# RT58X register map
Series: ARMv8-M Mainline; File version: 1.0
CPU: CM3 r0p0, little endian, MPU, no FPU, VTOR, 3 interrupt priority bits
Registers are 32-bit, read-write, reset 0x0 unless marked. A register's access mark holds for its fields unless they carry their own. Offsets are from the block's base; [hi:lo] are bit positions.

## RTC — RTC Register block
Base 0x40600000
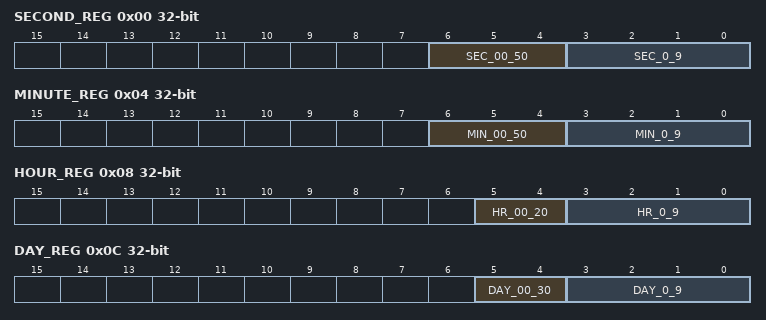
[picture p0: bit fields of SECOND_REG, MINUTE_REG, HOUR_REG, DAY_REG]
0x00 SECOND_REG — second
  [6:4] SEC_00_50 — Tens place of seconds (BCD)
    0=B_4_to_6 (Tens place of seconds (BCD))
  [3:0] SEC_0_9 — Units place of seconds (BCD)
    0=B_0_to_3 (Units place of seconds (BCD))
0x04 MINUTE_REG — minute
  [6:4] MIN_00_50 — Tens place of minutes (BCD)
    0=B_4_to_6 (Tens place of minutes (BCD))
  [3:0] MIN_0_9 — Units place of minutes (BCD)
    0=B_0_to_3 (Units place of minutes (BCD))
0x08 HOUR_REG — hour
  [5:4] HR_00_20 — Tens place of hours (BCD)
    0=B_4_to_5 (Tens place of hours (BCD))
  [3:0] HR_0_9 — Units place of hours (BCD)
    0=B_0_to_3 (Units place of hours (BCD))
0x0C DAY_REG — day
  [5:4] DAY_00_30 — Tens place of days (BCD)
    0=B_4_to_5 (Tens place of days (BCD))
  [3:0] DAY_0_9 — Units place of days (BCD)
    0=B_0_to_3 (Units place of days (BCD))
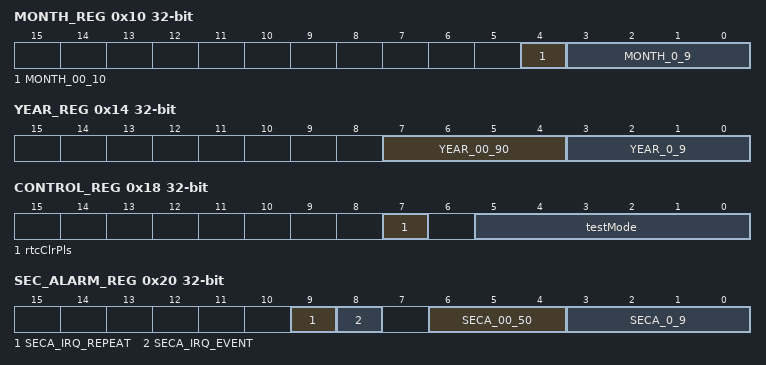
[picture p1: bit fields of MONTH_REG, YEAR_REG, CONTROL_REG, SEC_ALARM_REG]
0x10 MONTH_REG — month
  [4] MONTH_00_10 — Tens place of months (BCD)
    0=B_4 (Tens place of months (BCD))
  [3:0] MONTH_0_9 — Units place of months (BCD)
    0=B_0_to_3 (Units place of months (BCD))
0x14 YEAR_REG — year
  [7:4] YEAR_00_90 — Tens place of years (BCD)
    0=B_4_to_7 (Tens place of years (BCD))
  [3:0] YEAR_0_9 — Units place of years (BCD)
    0=B_0_to_3 (Units place of years (BCD))
0x18 CONTROL_REG — control
  [7] rtcClrPls — When 1 is written, creates a pulse on the clk32k domain to clear all counters and values there to their initial state. A write of 0 to this bit has no effect. Read: 1=Clear in progress, 0=Clear done.
    0=B_7 (When 1 is written, creates a pulse on the clk32k domain to clear all counters and values there to their initial state. A write of 0 to this bit has no effect. Read: 1=Clear in progress, 0=Clear done.)
  [5:0] testMode — Used to speed up Time Unit counters for test. If a bit is set to 1, then the corresponding time unit counter will change on the same timing as Seconds. [0]=Unused, [1]=Minutes, [2]=Hours, [3]=Days, [4]=Months, [5]=Years.
    0=B_0_to_5 (Used to speed up Time Unit counters for test. If a bit is set to 1, then the corresponding time unit counter will change on the same timing as Seconds. [0]=Unused, [1]=Minutes, [2]=Hours, [3]=Days, [4]=Months, [5]=Years.)
0x1C CLK_DIV_REG reset 0x7CFF — clk div
  [15:0] clkDiv — Clock Divisor for generating a 1Hz enable to the Seconds Counter. The Clock Divisor value (D) and the input clock frequency (F) are related by the following equation: D = F - 1
0x20 SEC_ALARM_REG — sec alarm
  [9] SECA_IRQ_REPEAT — When set, configures the event interrupt to trigger every second. When clear, seconds = seconds alarm for the event interrupt to be triggered.
    0=B_9 (When set, configures the event interrupt to trigger every second. When clear, seconds = seconds alarm for the event interrupt to be triggered.)
  [8] SECA_IRQ_EVENT — When set, configures the seconds interrupt to trigger every second. When clear, the seconds interrupt will be triggered once per minute, when seconds = seconds alarm.
    0=B_8 (When set, configures the seconds interrupt to trigger every second. When clear, the seconds interrupt will be triggered once per minute, when seconds = seconds alarm.)
  [6:4] SECA_00_50 — Tens place of seconds alarm (BCD)
    0=B_4_to_6 (Tens place of seconds alarm (BCD))
  [3:0] SECA_0_9 — Units place of seconds alarm (BCD)
    0=B_0_to_3 (Units place of seconds alarm (BCD))
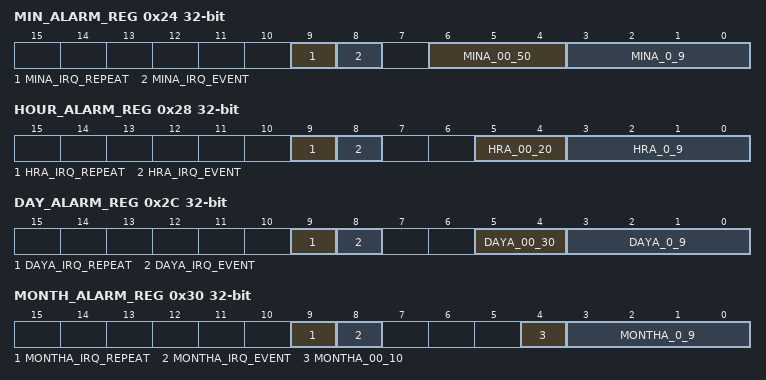
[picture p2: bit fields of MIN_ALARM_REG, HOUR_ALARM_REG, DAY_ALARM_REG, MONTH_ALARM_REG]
0x24 MIN_ALARM_REG — min alarm
  [9] MINA_IRQ_REPEAT — Note: This field is relevant only when SECA_IRQ_REPEAT is NOT set. When set, configures the event interrupt to trigger every minute when seconds = seconds alarm. When clear, seconds = seconds alarm AND minutes = minutes alarm for the event interrupt to be triggered.
    0=B_9 (Note: This field is relevant only when SECA_IRQ_REPEAT is NOT set. When set, configures the event interrupt to trigger every minute when seconds = seconds alarm. When clear, seconds = seconds alarm AND minutes = minutes alarm for the event interrupt to be triggered.)
  [8] MINA_IRQ_EVENT — When set, configures the minutes interrupt to trigger on the first second in each new minute. When clear, the minutes interrupt will be triggered once per hour, on the first second of the minute in which minutes = minutes alarm.
    0=B_8 (When set, configures the minutes interrupt to trigger on the first second in each new minute. When clear, the minutes interrupt will be triggered once per hour, on the first second of the minute in which minutes = minutes alarm.)
  [6:4] MINA_00_50 — Tens place of minutes alarm (BCD)
    0=B_4_to_6 (Tens place of minutes alarm (BCD))
  [3:0] MINA_0_9 — Units place of minutes alarm (BCD)
    0=B_0_to_3 (Units place of minutes alarm (BCD))
0x28 HOUR_ALARM_REG — hour alarm
  [9] HRA_IRQ_REPEAT — Note: This field is relevant only when MINA_IRQ_REPEAT and SECA_IRQ_PEPEAT are NOT set. When set, configures the event interrupt to trigger every hour when seconds = seconds alarm AND minutes = minutes alarm. When clear, seconds = seconds alarm AND minutes = minutes alarm AND hours = hours alarm for the event interrupt to be triggered.
    0=B_9 (Note: This field is relevant only when MINA_IRQ_REPEAT and SECA_IRQ_PEPEAT are NOT set. When set, configures the event interrupt to trigger every hour when seconds = seconds alarm AND minutes = minutes alarm. When clear, seconds = seconds alarm AND minutes = minutes alarm AND hours = hours alarm for the event interrupt to be triggered.)
  [8] HRA_IRQ_EVENT — When set, configures the hours interrupt to trigger on the first second in each new hour. When clear, the hours interrupt will be triggered once per day, on the first second of the hour in which hours = hours alarm.
    0=B_8 (When set, configures the hours interrupt to trigger on the first second in each new hour. When clear, the hours interrupt will be triggered once per day, on the first second of the hour in which hours = hours alarm.)
  [5:4] HRA_00_20 — Tens place of hours alarm (BCD)
    0=B_4_to_5 (Tens place of hours alarm (BCD))
  [3:0] HRA_0_9 — Units place of hours alarm (BCD)
    0=B_0_to_3 (Units place of hours alarm (BCD))
0x2C DAY_ALARM_REG — day alarm
  [9] DAYA_IRQ_REPEAT — Note: This field is relevant only when HRA_IRQ_REPEAT, MINA_IRQ_REPEAT and SECA_IRQ_REPEAT are NOT set. When set, configures the event interrupt to trigger every day when seconds = seconds alarm AND minutes = minutes alarm AND hours = hours alarm. When clear, seconds = seconds alarm AND minutes = minutes alarm AND hours = hours alarm AND days = days alarm for the event interrupt to be triggered.
    0=B_9 (Note: This field is relevant only when HRA_IRQ_REPEAT, MINA_IRQ_REPEAT and SECA_IRQ_REPEAT are NOT set. When set, configures the event interrupt to trigger every day when seconds = seconds alarm AND minutes = minutes alarm AND hours = hours alarm. When clear, seconds = seconds alarm AND minutes = minutes alarm AND hours = hours alarm AND days = days alarm for the event interrupt to be triggered.)
  [8] DAYA_IRQ_EVENT — When set, configures the days interrupt to trigger on the first second in each new day. When clear, the days interrupt will be triggered once per month, on the first second of the day in which days = days alarm.
    0=B_8 (When set, configures the days interrupt to trigger on the first second in each new day. When clear, the days interrupt will be triggered once per month, on the first second of the day in which days = days alarm.)
  [5:4] DAYA_00_30 — Tens place of days alarm (BCD)
    0=B_4_to_5 (Tens place of days alarm (BCD))
  [3:0] DAYA_0_9 — Units place of days alarm (BCD)
    0=B_0_to_3 (Units place of days alarm (BCD))
0x30 MONTH_ALARM_REG — month alarm
  [9] MONTHA_IRQ_REPEAT — Note: This field is relevant only when DAYA_IRQ_REPEAT, HRA_IRQ_REPEAT, MINA_IRQ_REPEAT and SECA_IRQ_REPEAT are NOT set. When set configures the event interrupt to trigger every month when seconds = seconds alarm AND minutes = minutes alarm AND hours = hours alarm AND days = days alarm. When clear, seconds = seconds alarm AND minutes = minutes alarm AND hours = hours alarm AND days = days alarm AND months = months alarm for the event interrupt to be triggered.
    0=B_9 (Note: This field is relevant only when DAYA_IRQ_REPEAT, HRA_IRQ_REPEAT, MINA_IRQ_REPEAT and SECA_IRQ_REPEAT are NOT set. When set configures the event interrupt to trigger every month when seconds = seconds alarm AND minutes = minutes alarm AND hours = hours alarm AND days = days alarm. When clear, seconds = seconds alarm AND minutes = minutes alarm AND hours = hours alarm AND days = days alarm AND months = months alarm for the event interrupt to be triggered.)
  [8] MONTHA_IRQ_EVENT — When set, configures the months interrupt to trigger on the first second in each new month. When clear, the months interrupt will be triggered once per year, on the first second of the month in which months = months alarm.
    0=B_8 (When set, configures the months interrupt to trigger on the first second in each new month. When clear, the months interrupt will be triggered once per year, on the first second of the month in which months = months alarm.)
  [4] MONTHA_00_10 — Tens place of months alarm (BCD)
    0=B_4 (Tens place of months alarm (BCD))
  [3:0] MONTHA_0_9 — Units place of months alarm (BCD)
    0=B_0_to_3 (Units place of months alarm (BCD))
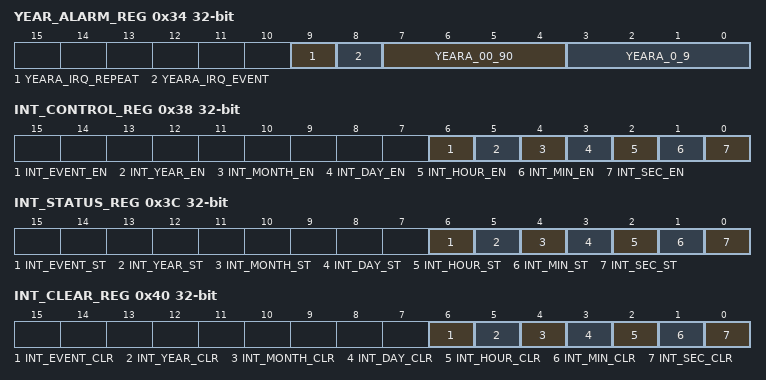
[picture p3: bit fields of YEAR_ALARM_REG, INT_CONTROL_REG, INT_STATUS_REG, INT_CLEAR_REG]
0x34 YEAR_ALARM_REG — year alarm
  [9] YEARA_IRQ_REPEAT — Note: This field is relevant only when MONTHA_IRQ_REPEAT, DAYA_IRQ_REPEAT, HRA_IRQ_REPEAT, MINA_IRQ_REPEAT and SECA_IRQ_REPEAT are NOT set. When set, configures the event interrupt to trigger every year when seconds = seconds alarm AND minutes = minutes alarm AND hours = hours alarm AND days = days alarm AND months = months alarm. When clear, seconds = seconds alarm AND minutes = minutes alarm AND hours = hours alarm AND days = days alarm AND months = months alarm AND years = years alarm for the event interrupt to be triggered.
    0=B_9 (Note: This field is relevant only when MONTHA_IRQ_REPEAT, DAYA_IRQ_REPEAT, HRA_IRQ_REPEAT, MINA_IRQ_REPEAT and SECA_IRQ_REPEAT are NOT set. When set, configures the event interrupt to trigger every year when seconds = seconds alarm AND minutes = minutes alarm AND hours = hours alarm AND days = days alarm AND months = months alarm. When clear, seconds = seconds alarm AND minutes = minutes alarm AND hours = hours alarm AND days = days alarm AND months = months alarm AND years = years alarm for the event interrupt to be triggered.)
  [8] YEARA_IRQ_EVENT — When set, configures the years interrupt to trigger on the first second in each new year. When clear, the years interrupt will be triggered once per century, on the first second of the year in which years = years alarm.
    0=B_8 (When set, configures the years interrupt to trigger on the first second in each new year. When clear, the years interrupt will be triggered once per century, on the first second of the year in which years = years alarm.)
  [7:4] YEARA_00_90 — Tens place of years alarm (BCD)
    0=B_4_to_7 (Tens place of years alarm (BCD))
  [3:0] YEARA_0_9 — Units place of years alarm (BCD)
    0=B_0_to_3 (Units place of years alarm (BCD))
0x38 INT_CONTROL_REG — int control
  [6] INT_EVENT_EN — Enable Event Alarm interrupt.
    0=B_6 (Enable Event Alarm interrupt.)
  [5] INT_YEAR_EN — Enable Year Alarm interrupt.
    0=B_5 (Enable Year Alarm interrupt.)
  [4] INT_MONTH_EN — Enable Month Alarm interrupt.
    0=B_4 (Enable Month Alarm interrupt.)
  [3] INT_DAY_EN — Enable Day Alarm interrupt.
    0=B_3 (Enable Day Alarm interrupt.)
  [2] INT_HOUR_EN — Enable Hour Alarm interrupt.
    0=B_2 (Enable Hour Alarm interrupt.)
  [1] INT_MIN_EN — Enable Minute Alarm interrupt.
    0=B_1 (Enable Minute Alarm interrupt.)
  [0] INT_SEC_EN — Enable Second Alarm interrupt.
    0=B_0 (Enable Second Alarm interrupt.)
0x3C INT_STATUS_REG ro — int status
  [6] INT_EVENT_ST — Event Alarm interrupt status.
    0=B_6 (Event Alarm interrupt status.)
  [5] INT_YEAR_ST — Year Alarm interrupt status.
    0=B_5 (Year Alarm interrupt status.)
  [4] INT_MONTH_ST — Month Alarm interrupt status.
    0=B_4 (Month Alarm interrupt status.)
  [3] INT_DAY_ST — Day Alarm interrupt status.
    0=B_3 (Day Alarm interrupt status.)
  [2] INT_HOUR_ST — Hour Alarm interrupt status.
    0=B_2 (Hour Alarm interrupt status.)
  [1] INT_MIN_ST — Minute Alarm interrupt status.
    0=B_1 (Minute Alarm interrupt status.)
  [0] INT_SEC_ST — Second Alarm interrupt status.
    0=B_0 (Second Alarm interrupt status.)
0x40 INT_CLEAR_REG — int clear
  [6] INT_EVENT_CLR wo — Clear Event Alarm interrupt.
    0=B_6 (Clear Event Alarm interrupt.)
  [5] INT_YEAR_CLR wo — Clear Year Alarm interrupt.
    0=B_5 (Clear Year Alarm interrupt.)
  [4] INT_MONTH_CLR wo — Clear Month Alarm interrupt.
    0=B_4 (Clear Month Alarm interrupt.)
  [3] INT_DAY_CLR wo — Clear Day Alarm interrupt.
    0=B_3 (Clear Day Alarm interrupt.)
  [2] INT_HOUR_CLR wo — Clear Hour Alarm interrupt.
    0=B_2 (Clear Hour Alarm interrupt.)
  [1] INT_MIN_CLR wo — Clear Minute Alarm interrupt.
    0=B_1 (Clear Minute Alarm interrupt.)
  [0] INT_SEC_CLR wo — Clear Second Alarm interrupt.
    0=B_0 (Clear Second Alarm interrupt.)
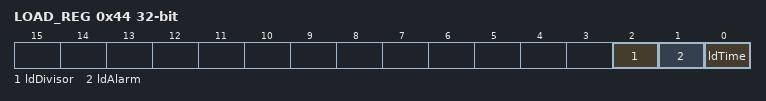
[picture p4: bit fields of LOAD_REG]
0x44 LOAD_REG — load
  [2] ldDivisor — Write 1 to update the clock divisor used on the 32kHz domain. For read, 0: Divisor update done. 1: Divisor update in progress
    0=B_2 (Write 1 to update the clock divisor used on the 32kHz domain. For read, 0: Divisor update done. 1: Divisor update in progress)
  [1] ldAlarm — Write 1 to update all alarm values on the 32kHz domain. For read, 0: Alarm value update done. 1: Alarm value update in progress,
    0=B_1 (Write 1 to update all alarm values on the 32kHz domain. For read, 0: Alarm value update done. 1: Alarm value update in progress,)
  [0] ldTime — Write 1 to update all time values on the 32kHz domain. For read, 0: Alarm value update done. 1: Time value update in progress
    0=B_0 (Write 1 to update all time values on the 32kHz domain. For read, 0: Alarm value update done. 1: Time value update in progress)
